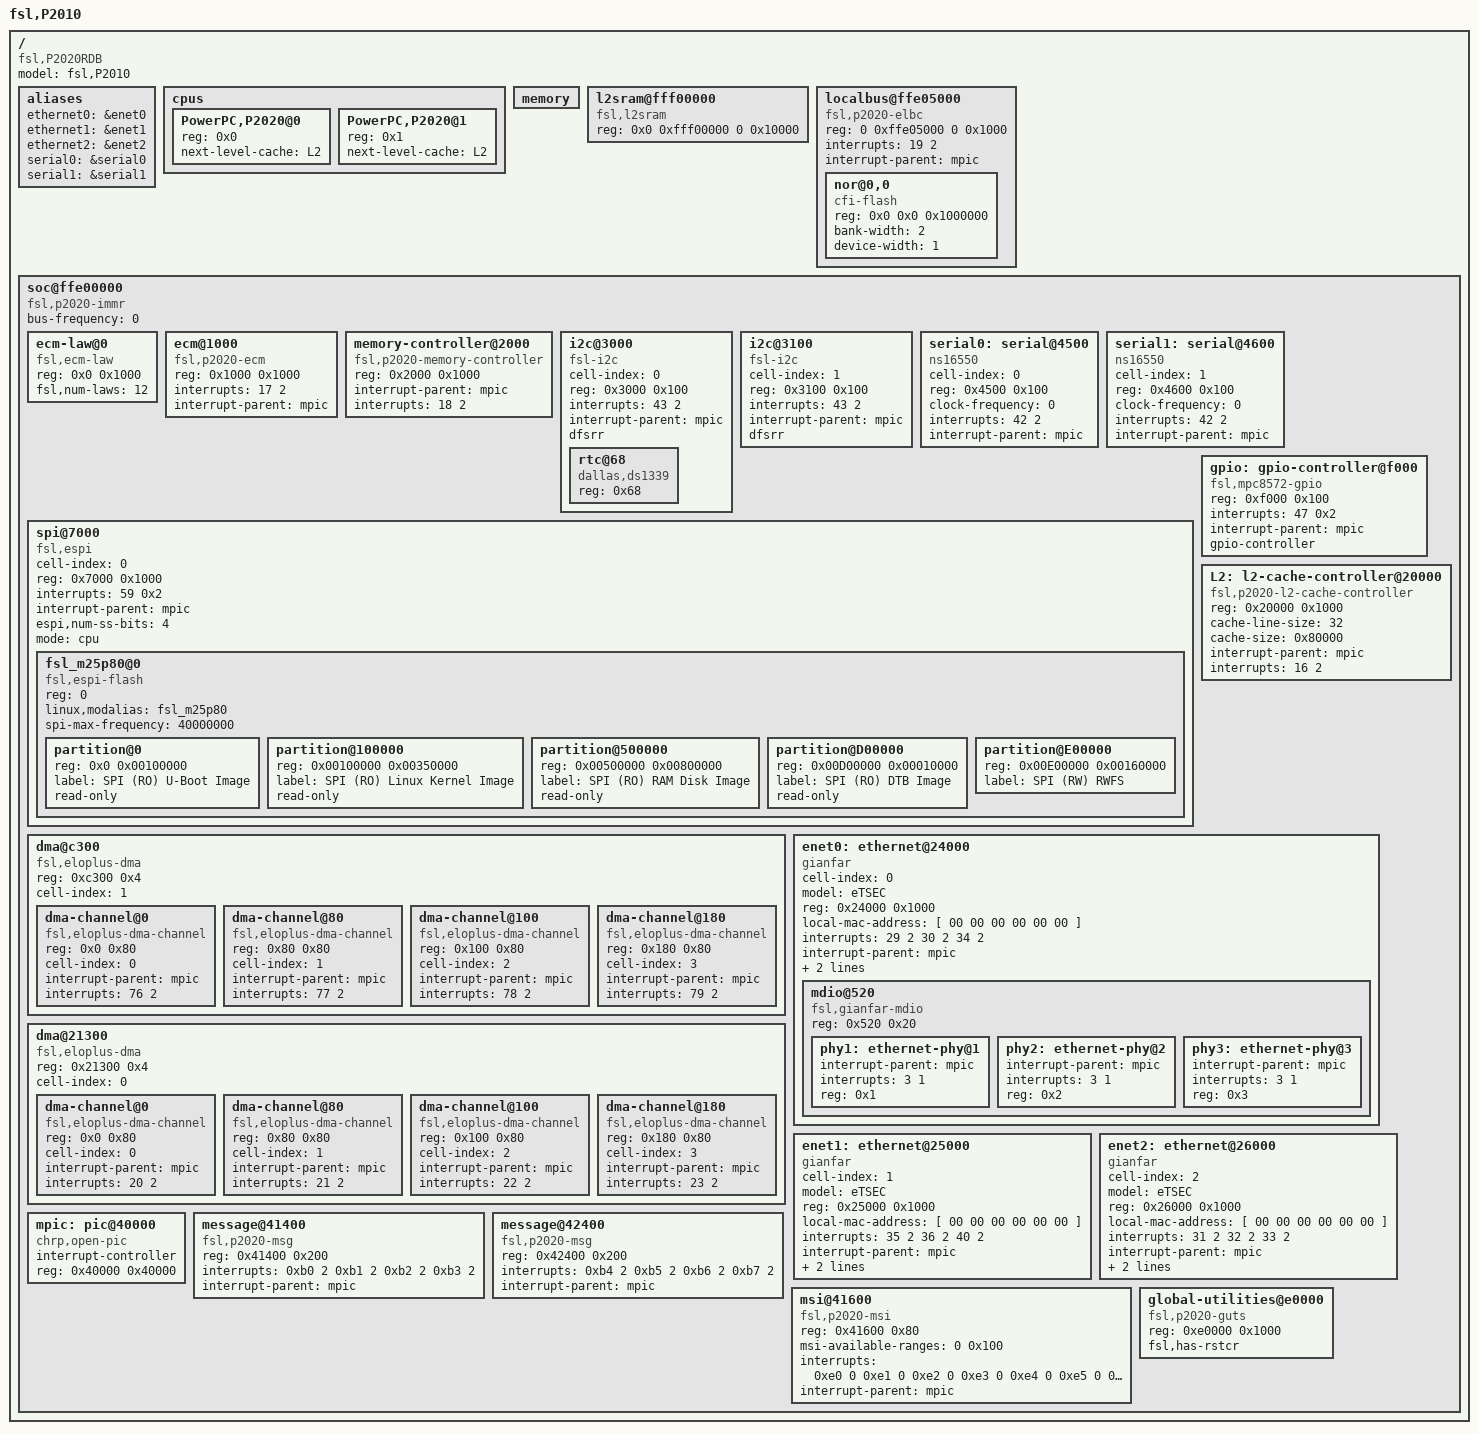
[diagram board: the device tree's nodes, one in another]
/*
 * P2010 RDB Device Tree Source
 *
 * Copyright 2010 Freescale Semiconductor Inc.
 *
 * This program is free software; you can redistribute  it and/or modify it
 * under  the terms of  the GNU General  Public License as published by the
 * Free Software Foundation;  either version 2 of the  License, or (at your
 * option) any later version.
 */

/dts-v1/;
/ {
	model = "fsl,P2010";
	compatible = "fsl,P2020RDB";
	#address-cells = <2>;
	#size-cells = <2>;

	aliases {
		ethernet0 = &enet0; 
		ethernet1 = &enet1; 
    	ethernet2 = &enet2;
		serial0 = &serial0;
		serial1 = &serial1;
	};

	cpus {
		#address-cells = <1>;
		#size-cells = <0>;

		PowerPC,P2020@0 {
			device_type = "cpu";
			reg = <0x0>;
			next-level-cache = <&L2>;
		};

		PowerPC,P2020@1 {
			device_type = "cpu";
			reg = <0x1>;
			next-level-cache = <&L2>;
		};
	};

	memory {
		device_type = "memory";
	};

	l2sram@fff00000 {
		device_type = "memory";
		compatible = "fsl,l2sram";
		reg = <0x0 0xfff00000 0 0x10000>;
	};

	localbus@ffe05000 {
		#address-cells = <2>;
		#size-cells = <1>;
		compatible = "fsl,p2020-elbc", "fsl,elbc", "simple-bus";
		reg = <0 0xffe05000 0 0x1000>;
		interrupts = <19 2>;
		interrupt-parent = <&mpic>;

		/* Cyclone3 PLIS Local bus */
	  	  ranges = <0x0 0x0 0x0 0xef000000 0x01000000
			        0x1 0x0 0x0 0xff000000 0x00040000
			        0x2 0x0 0x0 0xffb00000 0x00020000>;

		nor@0,0 {
			#address-cells = <1>;
			#size-cells = <1>;
			compatible = "cfi-flash";
			reg = <0x0 0x0 0x1000000>;
			bank-width = <2>;
			device-width = <1>;

		};

	};

	soc@ffe00000 {
		#address-cells = <1>;
		#size-cells = <1>;
		device_type = "soc";
		compatible = "fsl,p2020-immr", "simple-bus";
		ranges = <0x0  0x0 0xffe00000 0x100000>;
		bus-frequency = <0>;		// Filled out by uboot.

		ecm-law@0 {
			compatible = "fsl,ecm-law";
			reg = <0x0 0x1000>;
			fsl,num-laws = <12>;
		};

		ecm@1000 {
			compatible = "fsl,p2020-ecm", "fsl,ecm";
			reg = <0x1000 0x1000>;
			interrupts = <17 2>;
			interrupt-parent = <&mpic>;
		};

		memory-controller@2000 {
			compatible = "fsl,p2020-memory-controller";
			reg = <0x2000 0x1000>;
			interrupt-parent = <&mpic>;
			interrupts = <18 2>;
		};

		i2c@3000 {
			#address-cells = <1>;
			#size-cells = <0>;
			cell-index = <0>;
			compatible = "fsl-i2c";
			reg = <0x3000 0x100>;
			interrupts = <43 2>;
			interrupt-parent = <&mpic>;
			dfsrr;
			rtc@68 {
				compatible = "dallas,ds1339";
				reg = <0x68>;
			};
		};

		i2c@3100 {
			#address-cells = <1>;
			#size-cells = <0>;
			cell-index = <1>;
			compatible = "fsl-i2c";
			reg = <0x3100 0x100>;
			interrupts = <43 2>;
			interrupt-parent = <&mpic>;
			dfsrr;
		};

		serial0: serial@4500 {
			cell-index = <0>;
			device_type = "serial";
			compatible = "ns16550";
			reg = <0x4500 0x100>;
			clock-frequency = <0>;
			interrupts = <42 2>;
			interrupt-parent = <&mpic>;
		};

		serial1: serial@4600 {
			cell-index = <1>;
			device_type = "serial";
			compatible = "ns16550";
			reg = <0x4600 0x100>;
			clock-frequency = <0>;
			interrupts = <42 2>;
			interrupt-parent = <&mpic>;
		};

		spi@7000 {
			cell-index = <0>;
			#address-cells = <1>;
			#size-cells = <0>;
			compatible = "fsl,espi";
			reg = <0x7000 0x1000>;
			interrupts = <59 0x2>;
			interrupt-parent = <&mpic>;
			espi,num-ss-bits = <4>;
			mode = "cpu";
			fsl_m25p80@0 {
				#address-cells = <1>;
				#size-cells = <1>;
				compatible = "fsl,espi-flash";
				reg = <0>;
				linux,modalias = "fsl_m25p80";
				spi-max-frequency = <40000000>;

				partition@0 {
					/* 1Mb for u-boot Bootloader Image */
					reg = <0x0 0x00100000>;
					label = "SPI (RO) U-Boot Image";
					read-only;
				};

				partition@100000 {
					/* 3.5Mb for Linux kernel image */
					reg = <0x00100000 0x00350000>;
					label = "SPI (RO) Linux Kernel Image";
					read-only;
				};
				partition@500000 {
					/* 8MB for Linux Kernel Image */
					reg = <0x00500000 0x00800000>;
					label = "SPI (RO) RAM Disk Image";
				    read-only;
				};

				partition@D00000 {
					/* 65Kb for dtb image */
					reg = <0x00D00000 0x00010000>;
					label = "SPI (RO) DTB Image";
					read-only;
				};
                
   			        partition@E00000 {
					/* 2.0 Mb for script and router soft */
					reg = <0x00E00000 0x00160000>;
					label = "SPI (RW) RWFS";
				};
			
			};
		};
		
		dma@c300 {
			#address-cells = <1>;
			#size-cells = <1>;
			compatible = "fsl,eloplus-dma";
			reg = <0xc300 0x4>;
			ranges = <0x0 0xc100 0x200>;
			cell-index = <1>;
			dma-channel@0 {
				compatible = "fsl,eloplus-dma-channel";
				reg = <0x0 0x80>;
				cell-index = <0>;
				interrupt-parent = <&mpic>;
				interrupts = <76 2>;
			};
			dma-channel@80 {
				compatible = "fsl,eloplus-dma-channel";
				reg = <0x80 0x80>;
				cell-index = <1>;
				interrupt-parent = <&mpic>;
				interrupts = <77 2>;
			};
			dma-channel@100 {
				compatible = "fsl,eloplus-dma-channel";
				reg = <0x100 0x80>;
				cell-index = <2>;
				interrupt-parent = <&mpic>;
				interrupts = <78 2>;
			};
			dma-channel@180 {
				compatible = "fsl,eloplus-dma-channel";
				reg = <0x180 0x80>;
				cell-index = <3>;
				interrupt-parent = <&mpic>;
				interrupts = <79 2>;
			};
		};

		gpio: gpio-controller@f000 {
			#gpio-cells = <2>;
			compatible = "fsl,mpc8572-gpio";
			reg = <0xf000 0x100>;
			interrupts = <47 0x2>;
			interrupt-parent = <&mpic>;
			gpio-controller;
		};

		L2: l2-cache-controller@20000 {
			compatible = "fsl,p2020-l2-cache-controller";
			reg = <0x20000 0x1000>;
			cache-line-size = <32>;	// 32 bytes
			cache-size = <0x80000>; // L2,512K
			interrupt-parent = <&mpic>;
			interrupts = <16 2>;
		};

		dma@21300 {
			#address-cells = <1>;
			#size-cells = <1>;
			compatible = "fsl,eloplus-dma";
			reg = <0x21300 0x4>;
			ranges = <0x0 0x21100 0x200>;
			cell-index = <0>;
			dma-channel@0 {
				compatible = "fsl,eloplus-dma-channel";
				reg = <0x0 0x80>;
				cell-index = <0>;
				interrupt-parent = <&mpic>;
				interrupts = <20 2>;
			};
			dma-channel@80 {
				compatible = "fsl,eloplus-dma-channel";
				reg = <0x80 0x80>;
				cell-index = <1>;
				interrupt-parent = <&mpic>;
				interrupts = <21 2>;
			};
			dma-channel@100 {
				compatible = "fsl,eloplus-dma-channel";
				reg = <0x100 0x80>;
				cell-index = <2>;
				interrupt-parent = <&mpic>;
				interrupts = <22 2>;
			};
			dma-channel@180 {
				compatible = "fsl,eloplus-dma-channel";
				reg = <0x180 0x80>;
				cell-index = <3>;
				interrupt-parent = <&mpic>;
				interrupts = <23 2>;
			};
		};

		enet0: ethernet@24000 {
			#address-cells = <1>;
			#size-cells = <1>;
			cell-index = <0>;
			device_type = "network";
			model = "eTSEC";
			compatible = "gianfar";
			reg = <0x24000 0x1000>;
			ranges = <0x0 0x24000 0x1000>;
			local-mac-address = [ 00 00 00 00 00 00 ];
			interrupts = <29 2 30 2 34 2>;
			interrupt-parent = <&mpic>;
            phy-handle = <&phy1>;
			phy-connection-type = "rmii";

			mdio@520 {
				#address-cells = <1>;
				#size-cells = <0>;
				compatible = "fsl,gianfar-mdio";
				reg = <0x520 0x20>;

				phy1: ethernet-phy@1 {
					interrupt-parent = <&mpic>;
					interrupts = <3 1>;
					reg = <0x1>;
				};
			
			    phy2: ethernet-phy@2 {
					interrupt-parent = <&mpic>;
					interrupts = <3 1>;
					reg = <0x2>;
				};
			
			   phy3: ethernet-phy@3 {
					interrupt-parent = <&mpic>;
					interrupts = <3 1>;
					reg = <0x3>;
				};
			
			};
		
		
		};
      
		enet1: ethernet@25000 {
			#address-cells = <1>;
			#size-cells = <1>;
			cell-index = <1>;
			device_type = "network";
			model = "eTSEC";
			compatible = "gianfar";
			reg = <0x25000 0x1000>;
			ranges = <0x0 0x25000 0x1000>;
			local-mac-address = [ 00 00 00 00 00 00 ];
			interrupts = <35 2 36 2 40 2>;
			interrupt-parent = <&mpic>;
			phy-handle = <&phy2>;
			phy-connection-type = "rmii";
            	   
		   
		};
        
		
		enet2: ethernet@26000 {
			#address-cells = <1>;
			#size-cells = <1>;
			cell-index = <2>;
			device_type = "network";
			model = "eTSEC";
			compatible = "gianfar";
			reg = <0x26000 0x1000>;
			ranges = <0x0 0x26000 0x1000>;
			local-mac-address = [ 00 00 00 00 00 00 ];
			interrupts = <31 2 32 2 33 2>;
			interrupt-parent = <&mpic>;
			phy-handle = <&phy3>;
			phy-connection-type = "rmii";
		   
		}; 

        /*Virtual Ethernet  <<->>Local BUS and CYC3 PLIS*/
        /*
        enet3: ethernet@22000 {
			#address-cells = <1>;
			#size-cells = <1>;
			cell-index = <3>;
			device_type = "network";
			model = "KeTSEC";
			compatible = "gianfar";
			reg = <0x22000 0x1000>;
			local-mac-address = [ 00 00 00 00 00 00 ];
			interrupts = <81 2 82 2 84 2>;
			interrupt-parent = <&mpic>;
			fixed-link = <1 1 100 0 0>;
			phy-connection-type = "rmii";
		};
        */
		mpic: pic@40000 {
			interrupt-controller;
			#address-cells = <0>;
			#interrupt-cells = <2>;
			reg = <0x40000 0x40000>;
			compatible = "chrp,open-pic";
			device_type = "open-pic";
		};

		message@41400 {
			compatible = "fsl,p2020-msg", "fsl,mpic-msg";
			reg = <0x41400 0x200>;
			interrupts = <
				0xb0 2
				0xb1 2
				0xb2 2
				0xb3 2>;
			interrupt-parent = <&mpic>;
		};

		message@42400 {
			compatible = "fsl,p2020-msg", "fsl,mpic-msg";
			reg = <0x42400 0x200>;
			interrupts = <
				0xb4 2
				0xb5 2
				0xb6 2
				0xb7 2>;
			interrupt-parent = <&mpic>;
		};

		msi@41600 {
			compatible = "fsl,p2020-msi", "fsl,mpic-msi";
			reg = <0x41600 0x80>;
			msi-available-ranges = <0 0x100>;
			interrupts = <
				0xe0 0
				0xe1 0
				0xe2 0
				0xe3 0
				0xe4 0
				0xe5 0
				0xe6 0
				0xe7 0>;
			interrupt-parent = <&mpic>;
		};

		global-utilities@e0000 {	//global utilities block
			compatible = "fsl,p2020-guts";
			reg = <0xe0000 0x1000>;
			fsl,has-rstcr;
		};
	};

};
